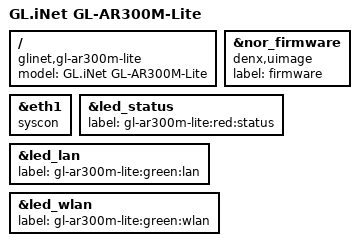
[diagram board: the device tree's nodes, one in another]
// SPDX-License-Identifier: GPL-2.0-or-later OR MIT

#include "qca9531_glinet_gl-ar300m.dtsi"

/ {
	compatible = "glinet,gl-ar300m-lite", "qca,qca9531";
	model = "GL.iNet GL-AR300M-Lite";
};

/delete-node/ &nand_flash;

&nor_firmware {
	compatible = "denx,uimage";
	label = "firmware";
};

// "Disable" unpopulated GMAC1

&eth1 {
	compatible = "syscon", "simple-mfd";
};

&led_status {
	label = "gl-ar300m-lite:red:status";
};

&led_lan {
	label = "gl-ar300m-lite:green:lan";
};

&led_wlan {
	label = "gl-ar300m-lite:green:wlan";
};
